VERSION ""

NS_ :

BS_:

BU_: CabinGuardECU VehicleGateway SafetyActuatorBus V2XTelematics

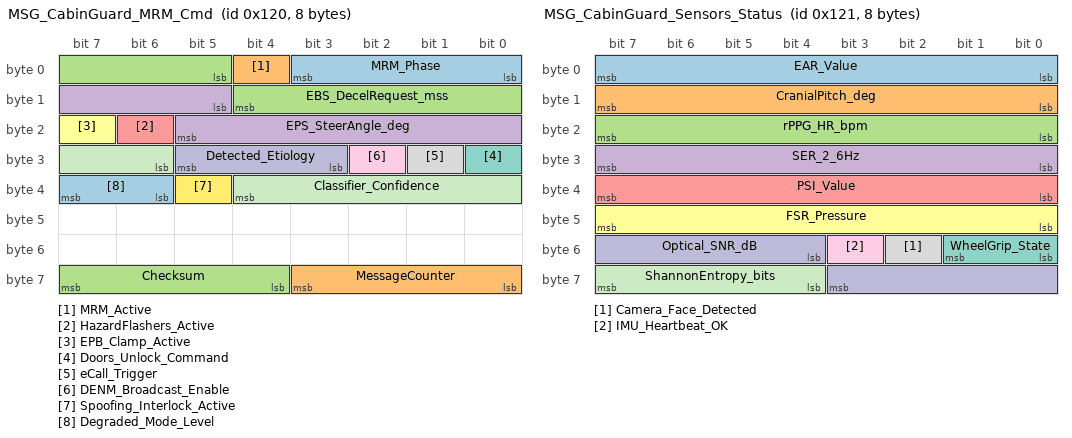
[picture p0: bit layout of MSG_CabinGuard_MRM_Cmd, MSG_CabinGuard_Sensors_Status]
BO_ 288 MSG_CabinGuard_MRM_Cmd: 8 CabinGuardECU
 SG_ MRM_Phase : 0|4@1+ (1,0) [0|15] "" VehicleGateway,SafetyActuatorBus
 SG_ MRM_Active : 4|1@1+ (1,0) [0|1] "" VehicleGateway,SafetyActuatorBus
 SG_ EBS_DecelRequest_mss : 5|8@1+ (0.05,-6.4) [-6.4|0.0] "m/s2" SafetyActuatorBus
 SG_ EPS_SteerAngle_deg : 13|9@1+ (0.5,-128.0) [-128.0|127.5] "deg" SafetyActuatorBus
 SG_ HazardFlashers_Active : 22|1@1+ (1,0) [0|1] "" SafetyActuatorBus
 SG_ EPB_Clamp_Active : 23|1@1+ (1,0) [0|1] "" SafetyActuatorBus
 SG_ Doors_Unlock_Command : 24|1@1+ (1,0) [0|1] "" SafetyActuatorBus
 SG_ eCall_Trigger : 25|1@1+ (1,0) [0|1] "" V2XTelematics
 SG_ DENM_Broadcast_Enable : 26|1@1+ (1,0) [0|1] "" V2XTelematics
 SG_ Detected_Etiology : 27|3@1+ (1,0) [0|7] "" VehicleGateway
 SG_ Classifier_Confidence : 30|7@1+ (0.01,0) [0|1.27] "" VehicleGateway
 SG_ Spoofing_Interlock_Active : 37|1@1+ (1,0) [0|1] "" VehicleGateway
 SG_ Degraded_Mode_Level : 38|2@1+ (1,0) [0|3] "" VehicleGateway
 SG_ MessageCounter : 56|4@1+ (1,0) [0|15] "" VehicleGateway
 SG_ Checksum : 60|4@1+ (1,0) [0|15] "" VehicleGateway

BO_ 289 MSG_CabinGuard_Sensors_Status: 8 CabinGuardECU
 SG_ EAR_Value : 0|8@1+ (0.002,0) [0|0.51] "" VehicleGateway
 SG_ CranialPitch_deg : 8|8@1+ (1,-128) [-128|127] "deg" VehicleGateway
 SG_ rPPG_HR_bpm : 16|8@1+ (0.5,0) [0|127.5] "bpm" VehicleGateway
 SG_ SER_2_6Hz : 24|8@1+ (0.005,0) [0|1.275] "" VehicleGateway
 SG_ PSI_Value : 32|8@1+ (0.004,0) [0|1.02] "" VehicleGateway
 SG_ FSR_Pressure : 40|8@1+ (0.004,0) [0|1.02] "" VehicleGateway
 SG_ WheelGrip_State : 48|2@1+ (1,0) [0|3] "" VehicleGateway
 SG_ Camera_Face_Detected : 50|1@1+ (1,0) [0|1] "" VehicleGateway
 SG_ IMU_Heartbeat_OK : 51|1@1+ (1,0) [0|1] "" VehicleGateway
 SG_ Optical_SNR_dB : 52|8@1+ (0.25,0) [0|63.75] "dB" VehicleGateway
 SG_ ShannonEntropy_bits : 60|4@1+ (0.1,0) [0|1.5] "bit" VehicleGateway

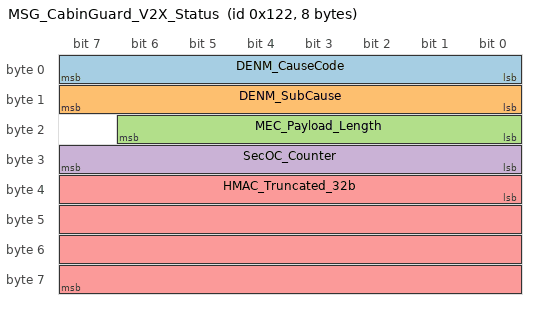
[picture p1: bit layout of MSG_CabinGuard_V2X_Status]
BO_ 290 MSG_CabinGuard_V2X_Status: 8 V2XTelematics
 SG_ DENM_CauseCode : 0|8@1+ (1,0) [0|255] "" VehicleGateway
 SG_ DENM_SubCause : 8|8@1+ (1,0) [0|255] "" VehicleGateway
 SG_ MEC_Payload_Length : 16|7@1+ (1,0) [0|127] "byte" VehicleGateway
 SG_ SecOC_Counter : 24|8@1+ (1,0) [0|255] "" VehicleGateway
 SG_ HMAC_Truncated_32b : 32|32@1+ (1,0) [0|4294967295] "" VehicleGateway

CM_ BU_ CabinGuardECU "CabinGuard-ADI primary AUTOSAR SecOC node (NVIDIA Jetson Orin NX 16GB)";
CM_ BU_ VehicleGateway "Central gateway: routes CabinGuard frames to vehicle CAN-FD backbone";
CM_ BU_ SafetyActuatorBus "AUTOSAR Safety Island: EBS, EPS, EPB, Hazard Flashers, Door Module";
CM_ BU_ V2XTelematics "ITS-G5 DSRC C-V2X combined telematics unit for DENM / MEC broadcast";

CM_ BO_ 288 "CabinGuard MRM Command frame. Transmitted at 10 Hz once any etiology is detected. SecOC FV applied per AUTOSAR CP 4.4 spec. CAN-FD bit rate 8 Mbit/s data phase.";
CM_ BO_ 289 "CabinGuard Sensor Fusion Status. Diagnostic frame at 10 Hz for gateway logging and OBD-IX access.";
CM_ BO_ 290 "CabinGuard V2X ETSI DENM header and MEC payload control. Triggers ITS-G5 CAM/DENM broadcast.";

CM_ SG_ 288 MRM_Phase "0=Normal, 1=PreAlert, 2=Escalation, 3=Active MRM -3.2m/s2, 4=Standstill EPB clamped";
CM_ SG_ 288 Detected_Etiology "0=None, 1=Syncope, 2=Seizure, 3=SuddenCardiacArrest, 4=Hypoglycemia, 5=MicrosleepExtended, 6=Reserved, 7=Unknown";
CM_ SG_ 288 Degraded_Mode_Level "0=Nominal, 1=Degraded1(IMU+rPPG only), 2=Degraded2(rPPG+FSR+Grip), 3=Minimum(FSR+Grip)";
CM_ SG_ 289 WheelGrip_State "0=DISENGAGED, 1=ACTIVE, 2=CLENCHED, 3=Reserved";

BA_DEF_ SG_ "GenSigSendType" ENUM "cyclic" "event" "noMsgSendType";
BA_DEF_ MSG_ "GenMsgCycleTime" INT 0 10000;
BA_DEF_ MSG_ "GenMsgSendType" ENUM "cyclic" "event" "noMsgSendType";

BA_DEF_DEF_ "GenSigSendType" "cyclic";
BA_DEF_DEF_ "GenMsgCycleTime" 100;
BA_DEF_DEF_ "GenMsgSendType" "cyclic";

VAL_ 288 MRM_Phase 0 "NORMAL" 1 "PHASE_1_PRE_ALERT" 2 "PHASE_2_ESCALATION" 3 "PHASE_3_ACTIVE_MRM" 4 "PHASE_4_STANDSTILL";
VAL_ 288 Detected_Etiology 0 "None" 1 "Syncope" 2 "Seizure" 3 "SuddenCardiacArrest" 4 "Hypoglycemia" 5 "Microsleep" 6 "Reserved" 7 "Unknown";
VAL_ 288 Degraded_Mode_Level 0 "Nominal" 1 "Degraded_1" 2 "Degraded_2" 3 "Minimum";
VAL_ 289 WheelGrip_State 0 "DISENGAGED" 1 "ACTIVE" 2 "CLENCHED" 3 "Reserved";
